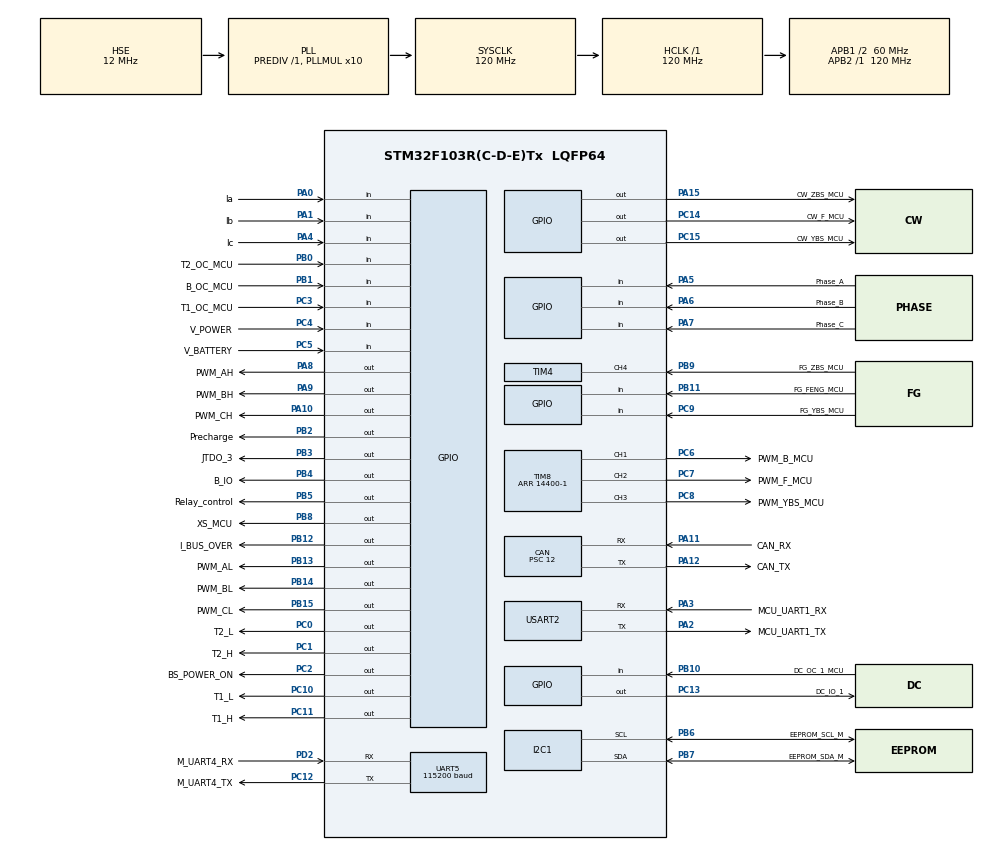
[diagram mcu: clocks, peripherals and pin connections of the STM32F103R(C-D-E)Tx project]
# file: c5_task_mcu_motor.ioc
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CAN.ABOM=DISABLE
CAN.BS1=CAN_BS1_5TQ
CAN.BS2=CAN_BS2_4TQ
CAN.CalculateBaudRate=500000
CAN.CalculateTimeBit=2000.00
CAN.CalculateTimeQuantum=200.0
CAN.Prescaler=12
CAN.SJW=CAN_SJW_1TQ
CAN.TXFP=DISABLE
Dma.Request0=USART2_RX
Dma.Request1=USART2_TX
Dma.USART2_RX.0.Direction=DMA_PERIPH_TO_MEMORY
Dma.USART2_RX.0.Instance=DMA1_Channel6
Dma.USART2_RX.0.MemDataAlignment=DMA_MDATAALIGN_BYTE
Dma.USART2_RX.0.MemInc=DMA_MINC_ENABLE
Dma.USART2_RX.0.Mode=DMA_CIRCULAR
Dma.USART2_RX.0.PeriphDataAlignment=DMA_PDATAALIGN_BYTE
Dma.USART2_RX.0.PeriphInc=DMA_PINC_DISABLE
Dma.USART2_RX.0.Priority=DMA_PRIORITY_VERY_HIGH
Dma.USART2_TX.1.Direction=DMA_MEMORY_TO_PERIPH
Dma.USART2_TX.1.Instance=DMA1_Channel7
Dma.USART2_TX.1.MemDataAlignment=DMA_MDATAALIGN_BYTE
Dma.USART2_TX.1.MemInc=DMA_MINC_ENABLE
Dma.USART2_TX.1.Mode=DMA_NORMAL
Dma.USART2_TX.1.PeriphDataAlignment=DMA_PDATAALIGN_BYTE
Dma.USART2_TX.1.PeriphInc=DMA_PINC_DISABLE
Dma.USART2_TX.1.Priority=DMA_PRIORITY_VERY_HIGH
FREERTOS.Events01=sys_suber_sunction_motor,Dynamic,NULL;sys_suber_fan_motor,Dynamic,NULL;sys_suber_detection,Dynamic,NULL;sys_suber_clean_ctrl,Dynamic,NULL;sys_suber_roll_motor,Dynamic,NULL;sys_suber_test,Dynamic,NULL;sys_suber_modbus_ota,Dynamic,NULL;sys_pub,Dynamic,NULL
FREERTOS.Queues01=topic_sunction_motor,1,clean_module_ctrl_st,0,Dynamic,NULL,NULL;topic_roll_brush_motor,1,clean_module_ctrl_st,0,Dynamic,NULL,NULL;topic_water_dist_pump,1,clean_module_ctrl_st,0,Dynamic,NULL,NULL;topic_side_brush_motor,1,clean_module_ctrl_st,0,Dynamic,NULL,NULL;topic_push_rod_motor_1,1,clean_module_ctrl_st,0,Dynamic,NULL,NULL;topic_push_rod_motor_2,1,clean_module_ctrl_st,0,Dynamic,NULL,NULL;topic_fan_motor_speed_set,1,clean_module_ctrl_st,0,Dynamic,NULL,NULL;topic_fan_motor_speed_fbk,1,clean_module_ctrl_st,0,Dynamic,NULL,NULL;topic_fan_motor_error_code,1,clean_module_ctrl_st,0,Dynamic,NULL,NULL;topic_update_file_recv,1,clean_module_ctrl_st,0,Dynamic,NULL,NULL;topic_update_enter_boot,1,clean_module_ctrl_st,0,Dynamic,NULL,NULL;topic_water_valve_clean,1,clean_module_ctrl_st,0,Dynamic,NULL,NULL
FREERTOS.Tasks01=defaultTask,8,1536,StartDefaultTask,As weak,NULL,Dynamic,NULL,NULL;task_shell,8,256,task_shell_run,As weak,NULL,Dynamic,NULL,NULL;device_run,16,512,device_run_thread_entry,As weak,NULL,Dynamic,NULL,NULL;det_thread,17,512,detection_device_thread_entry,As weak,NULL,Dynamic,NULL,NULL;can_rx,16,512,can_rx_thread,As weak,NULL,Dynamic,NULL,NULL;fan_motor_speed__set,16,256,fan_motor_thread,As weak,NULL,Dynamic,NULL,NULL;easylog_thread,16,256,task_fal_log_run,As weak,NULL,Dynamic,NULL,NULL;task_fal_pubsub,40,128,task_fal_pubsub_run,As weak,NULL,Dynamic,NULL,NULL;pal_ctl,8,1024,pal_ctl_thread,As weak,NULL,Dynamic,NULL,NULL
FREERTOS.configGENERATE_RUN_TIME_STATS=1
FREERTOS.configMAX_TASK_NAME_LEN=32
FREERTOS.configTOTAL_HEAP_SIZE=30000
FREERTOS.configUSE_IDLE_HOOK=0
FREERTOS.configUSE_STATS_FORMATTING_FUNCTIONS=1
FREERTOS.configUSE_TICK_HOOK=0
IWDG.Prescaler=IWDG_PRESCALER_256
Mcu.Family=STM32F1
Mcu.Name=STM32F103R(C-D-E)Tx
Mcu.Package=LQFP64
NVIC.DMA1_Channel6_IRQn=true\:5\:0\:false\:false\:true\:true\:false\:true
NVIC.DMA1_Channel7_IRQn=true\:5\:0\:false\:false\:true\:true\:false\:true
NVIC.PriorityGroup=NVIC_PRIORITYGROUP_4
NVIC.TIM4_IRQn=true\:5\:0\:false\:false\:true\:true\:true\:true
NVIC.TIM5_IRQn=true\:15\:0\:false\:false\:true\:false\:false\:true
NVIC.TimeBase=TIM5_IRQn
NVIC.TimeBaseIP=TIM5
NVIC.UART5_IRQn=true\:5\:0\:false\:false\:true\:true\:true\:true
NVIC.USART2_IRQn=true\:5\:0\:false\:false\:true\:true\:true\:true
PA0-WKUP.GPIO_Label=Ia
PA0-WKUP.Signal=GPIO_Input
PA1.GPIO_Label=Ib
PA1.Signal=GPIO_Input
PA10.GPIO_Label=PWM_CH
PA10.Signal=GPIO_Output
PA11.GPIO_Label=CAN_RX
PA11.GPIO_PuPd=GPIO_NOPULL
PA11.Mode=CAN_Activate
PA11.Signal=CAN_RX
PA12.GPIO_Label=CAN_TX
PA12.Mode=CAN_Activate
PA12.Signal=CAN_TX
PA13.GPIO_Label=SWDIO
PA13.Mode=Serial_Wire
PA13.Signal=SYS_JTMS-SWDIO
PA14.GPIO_Label=SWCLK
PA14.Mode=Serial_Wire
PA14.Signal=SYS_JTCK-SWCLK
PA15.GPIO_Label=CW_ZBS_MCU
PA15.Signal=GPIO_Output
PA2.GPIO_Label=MCU_UART1_TX
PA2.Mode=Asynchronous
PA2.Signal=USART2_TX
PA3.GPIO_Label=MCU_UART1_RX
PA3.Mode=Asynchronous
PA3.Signal=USART2_RX
PA4.GPIO_Label=Ic
PA4.Signal=GPIO_Input
PA5.GPIO_Label=Phase_A
PA5.Signal=GPIO_Input
PA6.GPIO_Label=Phase_B
PA6.Signal=GPIO_Input
PA7.GPIO_Label=Phase_C
PA7.Signal=GPIO_Input
PA8.GPIO_Label=PWM_AH
PA8.Signal=GPIO_Output
PA9.GPIO_Label=PWM_BH
PA9.Signal=GPIO_Output
PB0.GPIO_Label=T2_OC_MCU
PB0.Signal=GPIO_Input
PB1.GPIO_Label=B_OC_MCU
PB1.Signal=GPIO_Input
PB10.GPIO_Label=DC_OC_1_MCU
PB10.Signal=GPIO_Input
PB11.GPIO_Label=FG_FENG_MCU
PB11.Signal=GPIO_Input
PB12.GPIO_Label=I_BUS_OVER
PB12.Signal=GPIO_Output
PB13.GPIO_Label=PWM_AL
PB13.Signal=GPIO_Output
PB14.GPIO_Label=PWM_BL
PB14.Signal=GPIO_Output
PB15.GPIO_Label=PWM_CL
PB15.Signal=GPIO_Output
PB2.GPIO_Label=Precharge
PB2.Signal=GPIO_Output
PB3.GPIO_Label=JTDO_3
PB3.Signal=GPIO_Output
PB4.GPIO_Label=B_IO
PB4.Signal=GPIO_Output
PB5.GPIO_Label=Relay_control
PB5.GPIO_PuPd=GPIO_PULLUP
PB5.PinState=GPIO_PIN_RESET
PB5.Signal=GPIO_Output
PB6.GPIO_Label=EEPROM_SCL_M
PB6.Mode=I2C
PB6.Signal=I2C1_SCL
PB7.GPIO_Label=EEPROM_SDA_M
PB7.Mode=I2C
PB7.Signal=I2C1_SDA
PB8.GPIO_Label=XS_MCU
PB8.Signal=GPIO_Output
PB9.GPIO_Label=FG_ZBS_MCU
PB9.Signal=S_TIM4_CH4
PC0.GPIO_Label=T2_L
PC0.PinState=GPIO_PIN_RESET
PC0.Signal=GPIO_Output
PC1.GPIO_Label=T2_H
PC1.Signal=GPIO_Output
PC10.GPIO_Label=T1_L
PC10.Signal=GPIO_Output
PC11.GPIO_Label=T1_H
PC11.Signal=GPIO_Output
PC12.GPIO_Label=M_UART4_TX
PC12.Mode=Asynchronous
PC12.Signal=UART5_TX
PC13-TAMPER-RTC.GPIO_Label=DC_IO_1
PC13-TAMPER-RTC.GPIO_PuPd=GPIO_PULLUP
PC13-TAMPER-RTC.PinState=GPIO_PIN_RESET
PC13-TAMPER-RTC.Signal=GPIO_Output
PC14-OSC32_IN.GPIO_Label=CW_F_MCU
PC14-OSC32_IN.Signal=GPIO_Output
PC15-OSC32_OUT.GPIO_Label=CW_YBS_MCU
PC15-OSC32_OUT.Signal=GPIO_Output
PC2.GPIO_Label=BS_POWER_ON
PC2.Signal=GPIO_Output
PC3.GPIO_Label=T1_OC_MCU
PC3.Signal=GPIO_Input
PC4.GPIO_Label=V_POWER
PC4.Signal=GPIO_Input
PC5.GPIO_Label=V_BATTERY
PC5.Signal=GPIO_Input
PC6.GPIO_Label=PWM_B_MCU
PC6.Signal=S_TIM8_CH1
PC7.GPIO_Label=PWM_F_MCU
PC7.Signal=S_TIM8_CH2
PC8.GPIO_Label=PWM_YBS_MCU
PC8.Signal=S_TIM8_CH3
PC9.GPIO_Label=FG_YBS_MCU
PC9.Signal=GPIO_Input
PD0-OSC_IN.GPIO_Label=OSC_IN
PD0-OSC_IN.Mode=HSE-External-Oscillator
PD0-OSC_IN.Signal=RCC_OSC_IN
PD1-OSC_OUT.GPIO_Label=OSC_OUT
PD1-OSC_OUT.Mode=HSE-External-Oscillator
PD1-OSC_OUT.Signal=RCC_OSC_OUT
PD2.GPIO_Label=M_UART4_RX
PD2.GPIO_PuPd=GPIO_PULLUP
PD2.Mode=Asynchronous
PD2.Signal=UART5_RX
ProjectManager.HeapSize=0x200
ProjectManager.StackSize=0x200
ProjectManager.TargetToolchain=Makefile
RCC.ADCPresc=RCC_ADCPCLK2_DIV6
RCC.AHBFreq_Value=120000000
RCC.APB1CLKDivider=RCC_HCLK_DIV2
RCC.APB1Freq_Value=60000000
RCC.APB1TimFreq_Value=120000000
RCC.APB2Freq_Value=120000000
RCC.APB2TimFreq_Value=120000000
RCC.HCLKFreq_Value=120000000
RCC.HSE_VALUE=12000000
RCC.PLLMUL=RCC_PLL_MUL10
RCC.PLLSourceVirtual=RCC_PLLSOURCE_HSE
RCC.SYSCLKFreq_VALUE=120000000
RCC.SYSCLKSource=RCC_SYSCLKSOURCE_PLLCLK
RCC.USBFreq_Value=120000000
RTC.AutoPrediv=RTC_AUTO_1_SECOND
RTC.Date=19
RTC.Month=RTC_MONTH_NOVEMBER
RTC.WeekDay=RTC_WEEKDAY_THURSDAY
RTC.Year=15
SH.S_TIM4_CH4.0=TIM4_CH4,Input_Capture4_from_TI4
SH.S_TIM8_CH1.0=TIM8_CH1,PWM Generation1 CH1
SH.S_TIM8_CH2.0=TIM8_CH2,PWM Generation2 CH2
SH.S_TIM8_CH3.0=TIM8_CH3,PWM Generation3 CH3
TIM4.AutoReloadPreload=TIM_AUTORELOAD_PRELOAD_ENABLE
TIM4.Channel-Input_Capture4_from_TI4=TIM_CHANNEL_4
TIM4.Period=65535
TIM4.Prescaler=119
TIM8.AutoReloadPreload=TIM_AUTORELOAD_PRELOAD_ENABLE
TIM8.Channel-PWM\ Generation1\ CH1=TIM_CHANNEL_1
TIM8.Channel-PWM\ Generation2\ CH2=TIM_CHANNEL_2
TIM8.Channel-PWM\ Generation3\ CH3=TIM_CHANNEL_3
TIM8.OCIdleState_2=TIM_OCIDLESTATE_SET
TIM8.OCPolarity_2=TIM_OCPOLARITY_LOW
TIM8.Period=14400-1
UART5.BaudRate=115200
UART5.VirtualMode=Asynchronous
USART2.VirtualMode=VM_ASYNC
VP_CRC_VS_CRC.Mode=CRC_Activate
VP_FREERTOS_VS_CMSIS_V2.Mode=CMSIS_V2
VP_IWDG_VS_IWDG.Mode=IWDG_Activate
VP_RTC_VS_RTC_Activate.Mode=RTC_Enabled
VP_RTC_VS_RTC_Calendar.Mode=RTC_Calendar
VP_SYS_VS_tim5.Mode=TIM5
VP_TIM4_VS_ClockSourceINT.Mode=Internal
VP_TIM8_VS_ClockSourceINT.Mode=Internal
board=custom

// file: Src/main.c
/* USER CODE BEGIN Header */
/**
 ******************************************************************************
 * @file           : main.c
 * @brief          : Main program body
 ******************************************************************************
 * @attention
 *
 * <h2><center>&copy; Copyright (c) 2021 STMicroelectronics.
 * All rights reserved.</center></h2>
 *
 * This software component is licensed by ST under BSD 3-Clause license,
 * the "License"; You may not use this file except in compliance with the
 * License. You may obtain a copy of the License at:
 *                        opensource.org/licenses/BSD-3-Clause
 *
 ******************************************************************************
 */
/* USER CODE END Header */
#include "main.h"
#include "cmsis_os.h"
#include "can.h"
#include "crc.h"
#include "dma.h"
#include "i2c.h"
#include "iwdg.h"
#include "rtc.h"
#include "tim.h"
#include "usart.h"
#include "gpio.h"

/* USER CODE BEGIN Includes */

#include "app.h"

/* USER CODE END Includes */

void SystemClock_Config(void);
void MX_FREERTOS_Init(void);

int main(void) {

    /* MCU Configuration--------------------------------------------------------*/

    /* Reset of all peripherals, Initializes the Flash interface and the Systick. */
    HAL_Init();

    /* Configure the system clock */
    SystemClock_Config();

    /* USER CODE BEGIN SysInit */
#ifdef IAP
    SCB->VTOR = FLASH_BASE | 0x00008200;
    // __set_FAULTMASK(0);
    // __enable_irq();
#endif
    /* USER CODE END SysInit */

    /* Initialize all configured peripherals */
    MX_GPIO_Init();
    MX_DMA_Init();
    MX_CAN_Init();
    MX_USART2_UART_Init();
    MX_UART5_Init();
    MX_CRC_Init();
    MX_IWDG_Init();
    MX_TIM8_Init();
    MX_TIM4_Init();
    MX_I2C1_Init();
    MX_RTC_Init();
    /* USER CODE BEGIN 2 */

    app_init();

    /* USER CODE END 2 */

    /* Init scheduler */
    osKernelInitialize(); /* Call init function for freertos objects (in freertos.c) */
    MX_FREERTOS_Init();
    /* Start scheduler */
    osKernelStart();

    /* We should never get here as control is now taken by the scheduler */
    /* Infinite loop */
    while (1) {

    }
}

void SystemClock_Config(void) {
    RCC_OscInitTypeDef       RCC_OscInitStruct = {0};
    RCC_ClkInitTypeDef       RCC_ClkInitStruct = {0};
    RCC_PeriphCLKInitTypeDef PeriphClkInit     = {0};

    /** Initializes the RCC Oscillators according to the specified parameters
     * in the RCC_OscInitTypeDef structure.
     */
    RCC_OscInitStruct.OscillatorType = RCC_OSCILLATORTYPE_LSI | RCC_OSCILLATORTYPE_HSE;
    RCC_OscInitStruct.HSEState       = RCC_HSE_ON;
    RCC_OscInitStruct.HSEPredivValue = RCC_HSE_PREDIV_DIV1;
    RCC_OscInitStruct.HSIState       = RCC_HSI_ON;
    RCC_OscInitStruct.LSIState       = RCC_LSI_ON;
    RCC_OscInitStruct.PLL.PLLState   = RCC_PLL_ON;
    RCC_OscInitStruct.PLL.PLLSource  = RCC_PLLSOURCE_HSE;
    RCC_OscInitStruct.PLL.PLLMUL     = RCC_PLL_MUL10;
    if (HAL_RCC_OscConfig(&RCC_OscInitStruct) != HAL_OK) {
        Error_Handler();
    }
    /** Initializes the CPU, AHB and APB buses clocks
     */
    RCC_ClkInitStruct.ClockType      = RCC_CLOCKTYPE_HCLK | RCC_CLOCKTYPE_SYSCLK | RCC_CLOCKTYPE_PCLK1 | RCC_CLOCKTYPE_PCLK2;
    RCC_ClkInitStruct.SYSCLKSource   = RCC_SYSCLKSOURCE_PLLCLK;
    RCC_ClkInitStruct.AHBCLKDivider  = RCC_SYSCLK_DIV1;
    RCC_ClkInitStruct.APB1CLKDivider = RCC_HCLK_DIV2;
    RCC_ClkInitStruct.APB2CLKDivider = RCC_HCLK_DIV1;

    if (HAL_RCC_ClockConfig(&RCC_ClkInitStruct, FLASH_LATENCY_2) != HAL_OK) {
        Error_Handler();
    }
    PeriphClkInit.PeriphClockSelection = RCC_PERIPHCLK_RTC;
    PeriphClkInit.RTCClockSelection    = RCC_RTCCLKSOURCE_LSI;
    if (HAL_RCCEx_PeriphCLKConfig(&PeriphClkInit) != HAL_OK) {
        Error_Handler();
    }
}

void HAL_TIM_PeriodElapsedCallback(TIM_HandleTypeDef *htim) {
    if (htim->Instance == TIM5) {
        HAL_IncTick();
    }
}

void Error_Handler(void) {
    __disable_irq();
    while (1) {
    }
}

/************************ (C) COPYRIGHT STMicroelectronics *****END OF FILE****/
